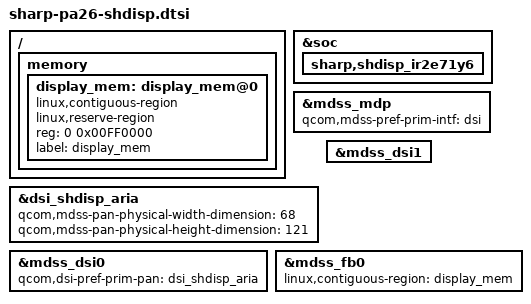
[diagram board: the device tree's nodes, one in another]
/* Copyright (c) 2014, The Linux Foundation. All rights reserved.
 *
 * This program is free software; you can redistribute it and/or modify
 * it under the terms of the GNU General Public License version 2 and
 * only version 2 as published by the Free Software Foundation.
 *
 * This program is distributed in the hope that it will be useful,
 * but WITHOUT ANY WARRANTY; without even the implied warranty of
 * MERCHANTABILITY or FITNESS FOR A PARTICULAR PURPOSE.  See the
 * GNU General Public License for more details.
 */

/include/ "sharp-shdisp-ir2e71y6.dtsi"
/include/ "sharp-shdisp-dsi-panel-aria-1080p-cmd.dtsi"

&soc {

	sharp,shdisp_ir2e71y6 {
		status = "ok";
	};
};

&mdss_mdp {
	qcom,mdss-pref-prim-intf = "dsi";

};

&dsi_shdisp_aria {
	status = "ok";

	qcom,mdss-pan-physical-width-dimension = <68>;
	qcom,mdss-pan-physical-height-dimension = <121>;
};

&mdss_dsi0 {
	qcom,dsi-pref-prim-pan=<&dsi_shdisp_aria>;

	/delete-property/ vdd-supply;
	/delete-property/ qcom,platform-reset-gpio;
	/delete-property/ qcom,platform-enable-gpio;

	/delete-node/ qcom,platform-supply-entry1;
};

&mdss_dsi1 {
	/delete-property/ vdd-supply;
};

/ {
	memory {
		display_mem: display_mem@0 {
			linux,contiguous-region;
			linux,reserve-region;
			reg = <0 0x00FF0000>;
			label = "display_mem";
		};
	};
};
&mdss_fb0 {
	linux,contiguous-region = <&display_mem>;
};
